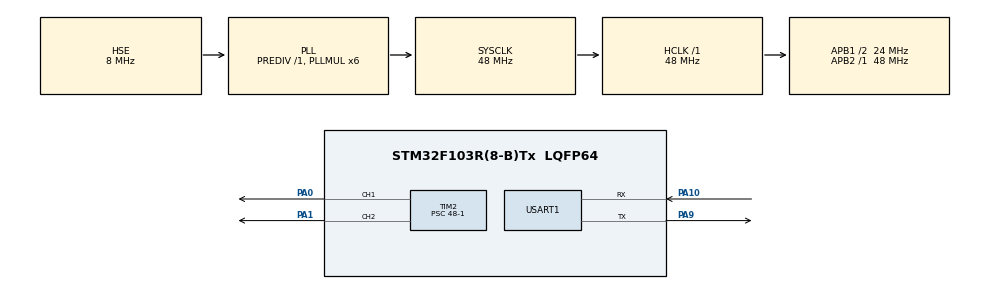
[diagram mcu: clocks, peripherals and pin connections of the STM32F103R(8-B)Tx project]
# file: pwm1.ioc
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Mcu.Family=STM32F1
Mcu.Name=STM32F103R(8-B)Tx
Mcu.Package=LQFP64
NVIC.PriorityGroup=NVIC_PRIORITYGROUP_4
PA0-WKUP.Signal=S_TIM2_CH1_ETR
PA1.Signal=S_TIM2_CH2
PA10.Mode=Asynchronous
PA10.Signal=USART1_RX
PA13.Mode=Serial_Wire
PA13.Signal=SYS_JTMS-SWDIO
PA14.Mode=Serial_Wire
PA14.Signal=SYS_JTCK-SWCLK
PA9.Mode=Asynchronous
PA9.Signal=USART1_TX
PD0-OSC_IN.Mode=HSE-External-Oscillator
PD0-OSC_IN.Signal=RCC_OSC_IN
PD1-OSC_OUT.Mode=HSE-External-Oscillator
PD1-OSC_OUT.Signal=RCC_OSC_OUT
ProjectManager.HeapSize=0x200
ProjectManager.StackSize=0x400
ProjectManager.TargetToolchain=MDK-ARM V5
RCC.AHBFreq_Value=48000000
RCC.APB1CLKDivider=RCC_HCLK_DIV2
RCC.APB1Freq_Value=24000000
RCC.APB1TimFreq_Value=48000000
RCC.APB2Freq_Value=48000000
RCC.APB2TimFreq_Value=48000000
RCC.HCLKFreq_Value=48000000
RCC.PLLMUL=RCC_PLL_MUL6
RCC.PLLSourceVirtual=RCC_PLLSOURCE_HSE
RCC.SYSCLKFreq_VALUE=48000000
RCC.SYSCLKSource=RCC_SYSCLKSOURCE_PLLCLK
RCC.USBFreq_Value=48000000
SH.S_TIM2_CH1_ETR.0=TIM2_CH1,PWM Generation1 CH1
SH.S_TIM2_CH2.0=TIM2_CH2,PWM Generation2 CH2
TIM2.Channel-PWM\ Generation1\ CH1=TIM_CHANNEL_1
TIM2.Channel-PWM\ Generation2\ CH2=TIM_CHANNEL_2
TIM2.Period=1000
TIM2.Prescaler=48-1
TIM2.Pulse-PWM\ Generation1\ CH1=100
TIM2.Pulse-PWM\ Generation2\ CH2=500
USART1.VirtualMode=VM_ASYNC
board=pwm1

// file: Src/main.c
#include "main.h"
#include "stm32f1xx_hal.h"

TIM_HandleTypeDef htim2;

UART_HandleTypeDef huart1;

/* USER CODE BEGIN PV */
/* Private variables ---------------------------------------------------------*/

/* USER CODE END PV */

void SystemClock_Config(void);
static void MX_GPIO_Init(void);
static void MX_TIM2_Init(void);
static void MX_USART1_UART_Init(void);
void HAL_TIM_MspPostInit(TIM_HandleTypeDef *htim);

/* USER CODE BEGIN PFP */
/* Private function prototypes -----------------------------------------------*/

/* USER CODE END PFP */

int main(void)
{

  /* MCU Configuration----------------------------------------------------------*/

  /* Reset of all peripherals, Initializes the Flash interface and the Systick. */
  HAL_Init();

  /* Configure the system clock */
  SystemClock_Config();

  /* Initialize all configured peripherals */
  MX_GPIO_Init();
  MX_TIM2_Init();
  MX_USART1_UART_Init();
  /* USER CODE BEGIN 2 */
	HAL_TIM_PWM_Start(&htim2, TIM_CHANNEL_1);
	HAL_TIMEx_PWMN_Start(&htim2, TIM_CHANNEL_1);

	HAL_TIM_PWM_Start(&htim2, TIM_CHANNEL_2);
	HAL_TIMEx_PWMN_Start(&htim2, TIM_CHANNEL_2);

  /* USER CODE END 2 */

  /* Infinite loop */
  while (1)
  {

  }

}

void SystemClock_Config(void)
{

  RCC_OscInitTypeDef RCC_OscInitStruct;
  RCC_ClkInitTypeDef RCC_ClkInitStruct;

    /**Initializes the CPU, AHB and APB busses clocks
    */
  RCC_OscInitStruct.OscillatorType = RCC_OSCILLATORTYPE_HSE;
  RCC_OscInitStruct.HSEState = RCC_HSE_ON;
  RCC_OscInitStruct.HSEPredivValue = RCC_HSE_PREDIV_DIV1;
  RCC_OscInitStruct.HSIState = RCC_HSI_ON;
  RCC_OscInitStruct.PLL.PLLState = RCC_PLL_ON;
  RCC_OscInitStruct.PLL.PLLSource = RCC_PLLSOURCE_HSE;
  RCC_OscInitStruct.PLL.PLLMUL = RCC_PLL_MUL6;
  if (HAL_RCC_OscConfig(&RCC_OscInitStruct) != HAL_OK)
  {
    _Error_Handler(__FILE__, __LINE__);
  }

    /**Initializes the CPU, AHB and APB busses clocks
    */
  RCC_ClkInitStruct.ClockType = RCC_CLOCKTYPE_HCLK|RCC_CLOCKTYPE_SYSCLK
                              |RCC_CLOCKTYPE_PCLK1|RCC_CLOCKTYPE_PCLK2;
  RCC_ClkInitStruct.SYSCLKSource = RCC_SYSCLKSOURCE_PLLCLK;
  RCC_ClkInitStruct.AHBCLKDivider = RCC_SYSCLK_DIV1;
  RCC_ClkInitStruct.APB1CLKDivider = RCC_HCLK_DIV2;
  RCC_ClkInitStruct.APB2CLKDivider = RCC_HCLK_DIV1;

  if (HAL_RCC_ClockConfig(&RCC_ClkInitStruct, FLASH_LATENCY_1) != HAL_OK)
  {
    _Error_Handler(__FILE__, __LINE__);
  }

    /**Configure the Systick interrupt time
    */
  HAL_SYSTICK_Config(HAL_RCC_GetHCLKFreq()/1000);

    /**Configure the Systick
    */
  HAL_SYSTICK_CLKSourceConfig(SYSTICK_CLKSOURCE_HCLK);

  /* SysTick_IRQn interrupt configuration */
  HAL_NVIC_SetPriority(SysTick_IRQn, 0, 0);
}

/* TIM2 init function */
static void MX_TIM2_Init(void)
{

  TIM_MasterConfigTypeDef sMasterConfig;
  TIM_OC_InitTypeDef sConfigOC;

  htim2.Instance = TIM2;
  htim2.Init.Prescaler = 48-1;
  htim2.Init.CounterMode = TIM_COUNTERMODE_UP;
  htim2.Init.Period = 1000;
  htim2.Init.ClockDivision = TIM_CLOCKDIVISION_DIV1;
  htim2.Init.AutoReloadPreload = TIM_AUTORELOAD_PRELOAD_DISABLE;
  if (HAL_TIM_PWM_Init(&htim2) != HAL_OK)
  {
    _Error_Handler(__FILE__, __LINE__);
  }

  sMasterConfig.MasterOutputTrigger = TIM_TRGO_RESET;
  sMasterConfig.MasterSlaveMode = TIM_MASTERSLAVEMODE_DISABLE;
  if (HAL_TIMEx_MasterConfigSynchronization(&htim2, &sMasterConfig) != HAL_OK)
  {
    _Error_Handler(__FILE__, __LINE__);
  }

  sConfigOC.OCMode = TIM_OCMODE_PWM1;
  sConfigOC.Pulse = 100;
  sConfigOC.OCPolarity = TIM_OCPOLARITY_HIGH;
  sConfigOC.OCFastMode = TIM_OCFAST_DISABLE;
  if (HAL_TIM_PWM_ConfigChannel(&htim2, &sConfigOC, TIM_CHANNEL_1) != HAL_OK)
  {
    _Error_Handler(__FILE__, __LINE__);
  }

  sConfigOC.Pulse = 500;
  if (HAL_TIM_PWM_ConfigChannel(&htim2, &sConfigOC, TIM_CHANNEL_2) != HAL_OK)
  {
    _Error_Handler(__FILE__, __LINE__);
  }

  HAL_TIM_MspPostInit(&htim2);

}

/* USART1 init function */
static void MX_USART1_UART_Init(void)
{

  huart1.Instance = USART1;
  huart1.Init.BaudRate = 115200;
  huart1.Init.WordLength = UART_WORDLENGTH_8B;
  huart1.Init.StopBits = UART_STOPBITS_1;
  huart1.Init.Parity = UART_PARITY_NONE;
  huart1.Init.Mode = UART_MODE_TX_RX;
  huart1.Init.HwFlowCtl = UART_HWCONTROL_NONE;
  huart1.Init.OverSampling = UART_OVERSAMPLING_16;
  if (HAL_UART_Init(&huart1) != HAL_OK)
  {
    _Error_Handler(__FILE__, __LINE__);
  }

}

/** Configure pins as
        * Analog
        * Input
        * Output
        * EVENT_OUT
        * EXTI
*/
static void MX_GPIO_Init(void)
{

  /* GPIO Ports Clock Enable */
  __HAL_RCC_GPIOD_CLK_ENABLE();
  __HAL_RCC_GPIOA_CLK_ENABLE();

}

void _Error_Handler(char *file, int line)
{
  while(1)
  {
  }
}
